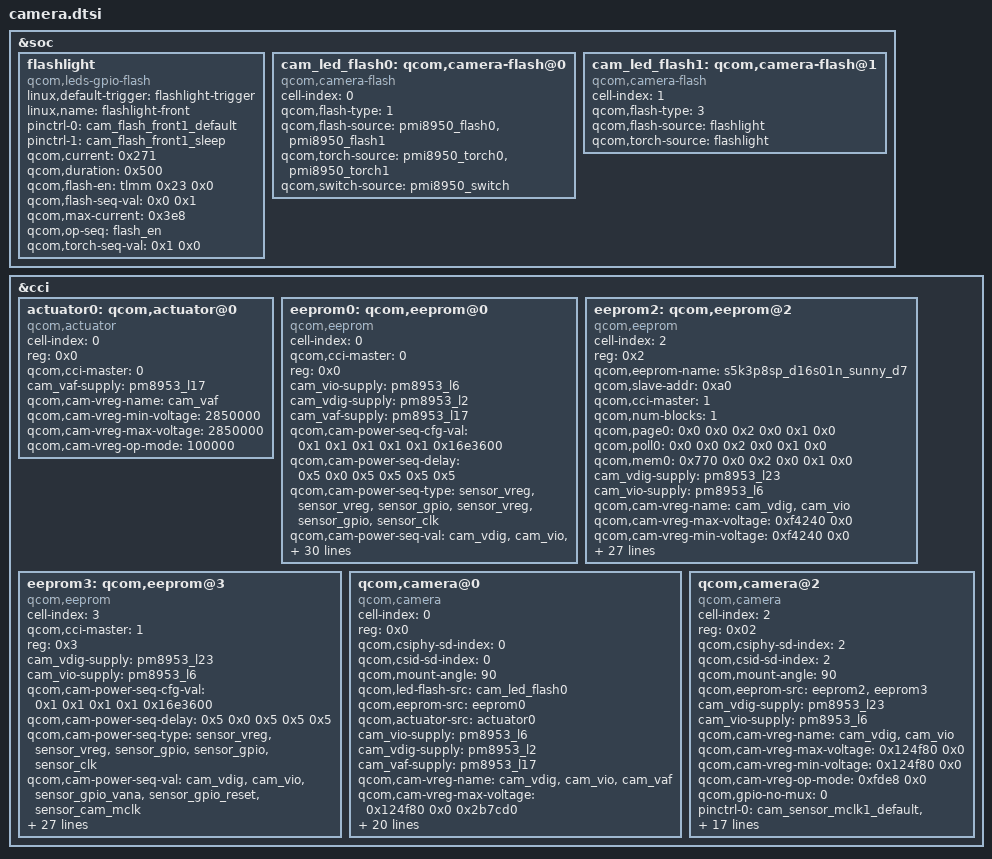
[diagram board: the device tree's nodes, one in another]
/*
 * Copyright (c) 2015-2016, The Linux Foundation. All rights reserved.
 *
 * This program is free software; you can redistribute it and/or modify
 * it under the terms of the GNU General Public License version 2 and
 * only version 2 as published by the Free Software Foundation.
 *
 * This program is distributed in the hope that it will be useful,
 * but WITHOUT ANY WARRANTY; without even the implied warranty of
 * MERCHANTABILITY or FITNESS FOR A PARTICULAR PURPOSE.  See the
 * GNU General Public License for more details.
 */

&soc {
	flashlight: flashlight {
		compatible = "qcom,leds-gpio-flash";
		linux,default-trigger = "flashlight-trigger";
		linux,name = "flashlight-front";
		pinctrl-0 = <&cam_flash_front1_default>;
		pinctrl-1 = <&cam_flash_front1_sleep>;
		pinctrl-names = "flash_default", "flash_sleep";
		qcom,current = <0x271>;
		qcom,duration = <0x500>;
		qcom,flash-en = <&tlmm 0x23 0x0>;
		qcom,flash-seq-val = <0x0 0x1>;
		qcom,max-current = <0x3e8>;
		qcom,op-seq = "flash_en";
		qcom,torch-seq-val = <0x1 0x0>;
		status = "okay";
	};
	cam_led_flash0: qcom,camera-flash@0 {
		cell-index = <0>;
		compatible = "qcom,camera-flash";
		qcom,flash-type = <1>;
		qcom,flash-source = <&pmi8950_flash0 &pmi8950_flash1>;
		qcom,torch-source = <&pmi8950_torch0 &pmi8950_torch1>;
		qcom,switch-source = <&pmi8950_switch>;
	};
	cam_led_flash1: qcom,camera-flash@1 {
		cell-index = <1>;
		compatible = "qcom,camera-flash";
		qcom,flash-type = <3>;
		qcom,flash-source = <&flashlight>;
		qcom,torch-source = <&flashlight>;
	};
};

&cci {
	actuator0: qcom,actuator@0 {
		cell-index = <0>;
		reg = <0x0>;
		compatible = "qcom,actuator";
		qcom,cci-master = <0>;
		cam_vaf-supply = <&pm8953_l17>;
		qcom,cam-vreg-name = "cam_vaf";
		qcom,cam-vreg-min-voltage = <2850000>;
		qcom,cam-vreg-max-voltage = <2850000>;
		qcom,cam-vreg-op-mode = <100000>;
	};

	eeprom0: qcom,eeprom@0 {
		cell-index = <0>;
		compatible = "qcom,eeprom";
		qcom,cci-master = <0>;
		reg = <0x0>;
		cam_vio-supply = <&pm8953_l6>;
		cam_vdig-supply = <&pm8953_l2>;
		cam_vaf-supply = <&pm8953_l17>;
		qcom,cam-power-seq-cfg-val = <0x1 0x1 0x1 0x1 0x1 0x16e3600>;
		qcom,cam-power-seq-delay = <0x5 0x0 0x5 0x5 0x5 0x5>;
		qcom,cam-power-seq-type = "sensor_vreg", "sensor_vreg", "sensor_gpio", "sensor_vreg", "sensor_gpio", "sensor_clk";
		qcom,cam-power-seq-val = "cam_vdig", "cam_vio", "sensor_gpio_vana", "cam_vaf", "sensor_gpio_reset", "sensor_cam_mclk";
		qcom,cam-vreg-name = "cam_vdig", "cam_vio", "cam_vaf";
		qcom,cam-vreg-max-voltage = <0x124f80 0x0 0x2b7cd0>;
		qcom,cam-vreg-min-voltage = <0x124f80 0x0 0x2b7cd0>;
		qcom,cam-vreg-op-mode = <0x30d40 0x0 0xf4240>;
		pinctrl-names = "cam_default", "cam_suspend";
		pinctrl-0 = <&cam_sensor_mclk0_default
				&cam_sensor_rear_default>;
		pinctrl-1 = <&cam_sensor_mclk0_sleep &cam_sensor_rear_sleep>;
		gpios = <&tlmm 26 0>,
			<&tlmm 40 0>,
			<&tlmm 23 0>;
		qcom,gpio-reset = <1>;
		qcom,gpio-vana = <2>;
		qcom,gpio-req-tbl-flags = <0x1 0x0 0x2>;
		qcom,gpio-req-tbl-num = <0x0 0x1 0x2>;
		qcom,gpio-req-tbl-label = "CAMIF_MCLK0",
			"CAM_RESET0",
			"CAM_VANA";
		status = "ok";
		clocks = <&clock_gcc clk_mclk0_clk_src>,
				<&clock_gcc clk_gcc_camss_mclk0_clk>;
		clock-names = "cam_src_clk", "cam_clk";
		qcom,clock-rates = <19200000 0>;
		qcom,eeprom-name = "ov12a10";
		qcom,i2c-freq-mode = <0x1>;
		qcom,mem0 = <0x1356 0x0 0x2 0x0 0x1 0x0>;
		qcom,num-blocks = <0x1>;
		qcom,page0 = <0x0 0x0 0x2 0x1 0x1 0x1>;
		qcom,poll0 = <0x0 0x0 0x2 0x0 0x1 0x1>;
		qcom,sensor-mode = <0x0>;
		qcom,slave-addr = <0xb0>;
	};

	eeprom2: qcom,eeprom@2 {
		cell-index = <2>;
		reg = <0x2>;
		qcom,eeprom-name = "s5k3p8sp_d16s01n_sunny_d7";
		compatible = "qcom,eeprom";
		qcom,slave-addr = <0xa0>;
		qcom,cci-master = <1>;
		qcom,num-blocks = <1>;

		qcom,page0 = <0x0 0x0 0x2 0x0 0x1 0x0>;
		qcom,poll0 = <0x0 0x0 0x2 0x0 0x1 0x0>;
		qcom,mem0 = <0x770 0x0 0x2 0x0 0x1 0x0>;

		cam_vdig-supply = <&pm8953_l23>;
		cam_vio-supply = <&pm8953_l6>;
		qcom,cam-vreg-name = "cam_vdig", "cam_vio";
		qcom,cam-vreg-max-voltage = <0xf4240 0x0>;
		qcom,cam-vreg-min-voltage = <0xf4240 0x0>;
		qcom,cam-vreg-op-mode = <0xfde8 0x0>;
		qcom,gpio-no-mux = <0>;
		pinctrl-names = "cam_default", "cam_suspend";
		pinctrl-0 = <&cam_sensor_mclk1_default
			&cam_sensor_front1_default>;
		pinctrl-1 = <&cam_sensor_mclk1_sleep &cam_sensor_front1_sleep>;
		gpios = <&tlmm 27 0>,
			<&tlmm 129 0>,
			<&tlmm 17 0>;
		qcom,gpio-vana = <0x2>;
		qcom,gpio-reset = <1>;
		qcom,gpio-req-tbl-num = <0 1 2>;
		qcom,gpio-req-tbl-flags = <0x1 0x0 0x2>;
		qcom,gpio-req-tbl-label = "CAMIF_MCLK2",
					  "CAM_RESET2",
					  "CAM_VANA";
		qcom,cam-power-seq-type = "sensor_vreg", "sensor_vreg", "sensor_gpio", "sensor_gpio", "sensor_clk";
		qcom,cam-power-seq-val = "cam_vdig", "cam_vio", "sensor_gpio_vana", "sensor_gpio_reset", "sensor_cam_mclk";
		qcom,cam-power-seq-cfg-val = <0x1 0x1 0x1 0x1 0x16e3600>;
		qcom,cam-power-seq-delay = <0x5 0x0 0x5 0x5 0x5>;
		status = "ok";
		clocks = <&clock_gcc clk_mclk1_clk_src>,
			<&clock_gcc clk_gcc_camss_mclk1_clk>;
		clock-names = "cam_src_clk", "cam_clk";
		qcom,clock-rates = <19200000 0>;
		qcom,i2c-freq-mode = <0x1>;
		qcom,sensor-mode = <0x0>;
	};

	eeprom3: qcom,eeprom@3 {
		cell-index = <3>;
		compatible = "qcom,eeprom";
		qcom,cci-master = <1>;
		reg = <0x3>;
		cam_vdig-supply = <&pm8953_l23>;
		cam_vio-supply = <&pm8953_l6>;
		qcom,cam-power-seq-cfg-val = <0x1 0x1 0x1 0x1 0x16e3600>;
		qcom,cam-power-seq-delay = <0x5 0x0 0x5 0x5 0x5>;
		qcom,cam-power-seq-type = "sensor_vreg", "sensor_vreg", "sensor_gpio", "sensor_gpio", "sensor_clk";
		qcom,cam-power-seq-val = "cam_vdig", "cam_vio", "sensor_gpio_vana", "sensor_gpio_reset", "sensor_cam_mclk";
		qcom,cam-vreg-name = "cam_vdig", "cam_vio";
		qcom,cam-vreg-min-voltage = <0xf4240 0x0>;
		qcom,cam-vreg-max-voltage = <0xf4240 0x0>;
		qcom,cam-vreg-op-mode = <0xfde8 0x0>;
		pinctrl-names = "cam_default", "cam_suspend";
		pinctrl-0 = <&cam_sensor_mclk1_default
				&cam_sensor_front1_default>;
		pinctrl-1 = <&cam_sensor_mclk1_sleep
				&cam_sensor_front1_sleep>;
		gpios = <&tlmm 27 0>,
			<&tlmm 129 0>,
			<&tlmm 17 0>;
		qcom,gpio-reset = <1>;
		qcom,gpio-req-tbl-num = <0 1 2>;
		qcom,gpio-req-tbl-flags = <1 0 2>;
		qcom,gpio-req-tbl-label = "CAMIF_MCLK2",
			"CAM_RESET2",
			"CAM_VANA";
		status = "ok";
		clocks = <&clock_gcc clk_mclk1_clk_src>,
				<&clock_gcc clk_gcc_camss_mclk1_clk>;
		clock-names = "cam_src_clk", "cam_clk";
		qcom,clock-rates = <19200000 0>;
		qcom,eeprom-name = "ov16885_ojf0541_ofilm_d7";
		qcom,gpio-no-mux = <0x0>;
		qcom,gpio-vana = <0x2>;
		qcom,i2c-freq-mode = <0x1>;
		qcom,mem0 = <0x770 0x0 0x2 0x0 0x1 0x0>;
		qcom,num-blocks = <0x1>;
		qcom,page0 = <0x0 0x0 0x2 0x0 0x1 0x0>;
		qcom,poll0 = <0x0 0x0 0x2 0x0 0x1 0x0>;
		qcom,sensor-mode = <0x0>;
		qcom,slave-addr = <0xa0>;
	};

	qcom,camera@0 {
		cell-index = <0>;
		compatible = "qcom,camera";
		reg = <0x0>;
		qcom,csiphy-sd-index = <0>;
		qcom,csid-sd-index = <0>;
		qcom,mount-angle = <90>;
		qcom,led-flash-src = <&cam_led_flash0>;
		qcom,eeprom-src = <&eeprom0>;
		qcom,actuator-src = <&actuator0>;
		cam_vio-supply = <&pm8953_l6>;
		cam_vdig-supply = <&pm8953_l2>;
		cam_vaf-supply = <&pm8953_l17>;
		qcom,cam-vreg-name = "cam_vdig", "cam_vio", "cam_vaf";
		qcom,cam-vreg-max-voltage = <0x124f80 0x0 0x2b7cd0>;
		qcom,cam-vreg-min-voltage = <0x124f80 0x0 0x2b7cd0>;
		qcom,cam-vreg-op-mode = <0x30d40 0x0 0xf4240>;
		pinctrl-names = "cam_default", "cam_suspend";
		pinctrl-0 = <&cam_sensor_mclk0_default &cam_sensor_rear_default>;
		pinctrl-1 = <&cam_sensor_mclk0_sleep &cam_sensor_rear_sleep>;
		gpios = <&tlmm 26 0>,
			<&tlmm 40 0>,
			<&tlmm 23 0>;
		qcom,gpio-reset = <1>;
		qcom,gpio-vana = <2>;
		qcom,gpio-req-tbl-num = <0x0 0x1 0x2>;
		qcom,gpio-req-tbl-flags = <0x1 0x0 0x2>;
		qcom,gpio-req-tbl-label = "CAMIF_MCLK0", "CAM_RESET0", "CAM_VANA";
		qcom,sensor-position = <0>;
		qcom,sensor-mode = <0>;
		qcom,cci-master = <0>;
		status = "ok";
		clocks = <&clock_gcc clk_mclk0_clk_src>,
				<&clock_gcc clk_gcc_camss_mclk0_clk>;
		clock-names = "cam_src_clk", "cam_clk";
		qcom,clock-rates = <24000000 0>;
	};

	qcom,camera@2 {
		cell-index = <2>;
		compatible = "qcom,camera";
		reg = <0x02>;
		qcom,csiphy-sd-index = <2>;
		qcom,csid-sd-index = <2>;
		qcom,mount-angle = <90>;
		qcom,eeprom-src = <&eeprom2 &eeprom3>;
		cam_vdig-supply = <&pm8953_l23>;
		cam_vio-supply = <&pm8953_l6>;
		qcom,cam-vreg-name = "cam_vdig", "cam_vio";
		qcom,cam-vreg-max-voltage = <0x124f80 0x0>;
		qcom,cam-vreg-min-voltage = <0x124f80 0x0>;
		qcom,cam-vreg-op-mode = <0xfde8 0x0>;
		qcom,gpio-no-mux = <0>;
		pinctrl-names = "cam_default", "cam_suspend";
		pinctrl-0 = <&cam_sensor_mclk1_default
				&cam_sensor_front1_default>;
		pinctrl-1 = <&cam_sensor_mclk1_sleep
				&cam_sensor_front1_sleep>;
		gpios = <&tlmm 27 0>,
			<&tlmm 129 0>,
			<&tlmm 22 0>;
		qcom,gpio-reset = <1>;
		qcom,gpio-vana = <0x2>;
		qcom,led-flash-src = <&cam_led_flash1>;
		qcom,gpio-req-tbl-num = <0 1 2>;
		qcom,gpio-req-tbl-flags = <0x1 0x0 0x2>;
		qcom,gpio-req-tbl-label = "CAMIF_MCLK2", "CAM_RESET2", "CAM_VANA";
		qcom,sensor-position = <1>;
		qcom,sensor-mode = <0>;
		qcom,cci-master = <1>;
		status = "ok";
		clocks = <&clock_gcc clk_mclk1_clk_src>,
			<&clock_gcc clk_gcc_camss_mclk1_clk>;
		clock-names = "cam_src_clk", "cam_clk";
		qcom,clock-rates = <24000000 0>;
	};
};
